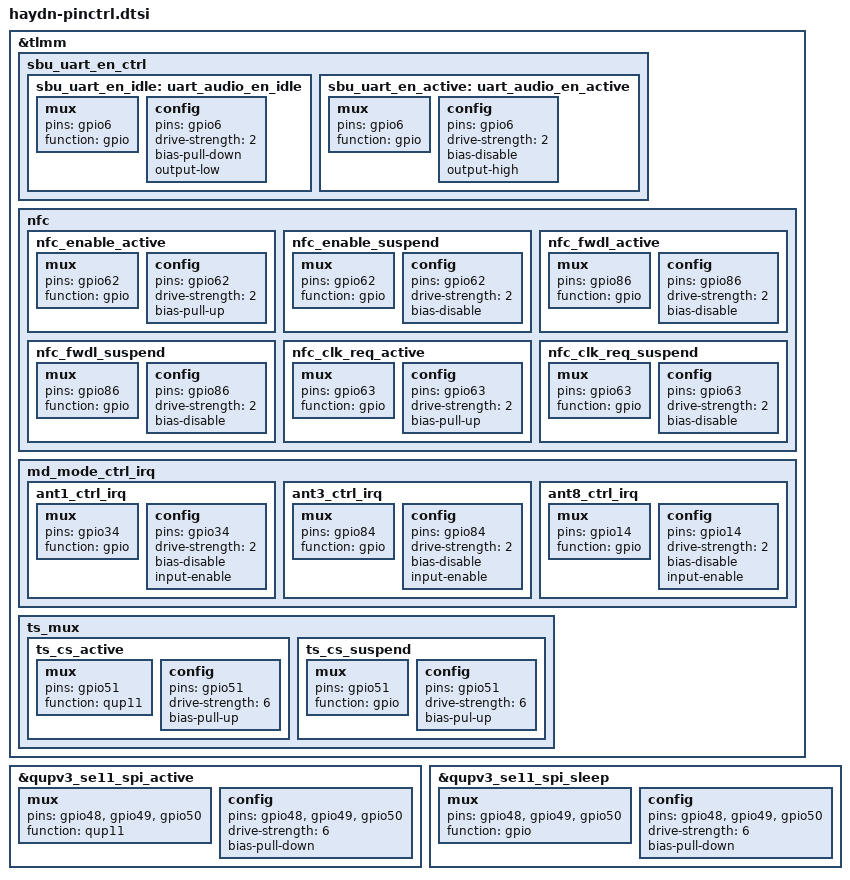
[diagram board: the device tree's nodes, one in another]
/*for haydn pinctrl */
&tlmm {
	sbu_uart_en_ctrl {
		sbu_uart_en_idle: uart_audio_en_idle {
			mux {
					pins = "gpio6";
					function = "gpio";
			};
			config {
					pins = "gpio6";
					drive-strength = <2>;
					bias-pull-down;
					output-low;
			};
		};

		sbu_uart_en_active: uart_audio_en_active {
			mux {
					pins = "gpio6";
					function = "gpio";
			};
			config {
						pins = "gpio6";
						drive-strength = <2>;
						bias-disable;
						output-high;
			};
		};
	};
	nfc {
			nfc_enable_active: nfc_enable_active {
				mux {
					pins = "gpio62";
					function = "gpio";
				};

				config {
					pins = "gpio62";
					drive-strength = <2>; /* 2 MA */
					bias-pull-up;
				};
			};

			nfc_enable_suspend: nfc_enable_suspend {
				mux {
					pins = "gpio62";
					function = "gpio";
				};

				config {
					pins = "gpio62";
					drive-strength = <2>; /* 2 MA */
					bias-disable;
				};
			};

			nfc_fwdl_active: nfc_fwdl_active {
				mux {
					/* 86: Firmware */
					pins = "gpio86";
					function = "gpio";
				};

				config {
					pins = "gpio86";
					drive-strength = <2>; /* 2 MA */
					bias-disable;
				};
			};

			nfc_fwdl_suspend: nfc_fwdl_suspend {
				mux {
					/*86: Firmware */
					pins = "gpio86";
					function = "gpio";
				};

				config {
					pins = "gpio86";
					drive-strength = <2>; /* 2 MA */
					bias-disable;
				};
			};

			nfc_clk_req_active: nfc_clk_req_active {
				/* active state */
				mux {
					/* GPIO 63: NFC CLOCK REQUEST */
					pins = "gpio63";
					function = "gpio";
				};

				config {
					pins = "gpio63";
					drive-strength = <2>; /* 2 MA */
					bias-pull-up;
				};
			};

			nfc_clk_req_suspend: nfc_clk_req_suspend {
				/* sleep state */
				mux {
					/* GPIO 63: NFC CLOCK REQUEST */
					pins = "gpio63";
					function = "gpio";
				};

				config {
					pins = "gpio63";
					drive-strength = <2>; /* 2 MA */
					bias-disable;
				};
			};
	};

	md_mode_ctrl_irq {
		ant1_ctrl_irq: ant1_ctrl_irq {
			mux {
				pins = "gpio34";
				function = "gpio";
			};

			config {
				pins = "gpio34";
				drive-strength = <2>;
				bias-disable;
				input-enable;
			};
		};

		ant3_ctrl_irq: ant3_ctrl_irq {
			mux {
				pins = "gpio84";
				function = "gpio";
			};

			config {
				pins = "gpio84";
				drive-strength = <2>;
				bias-disable;
				input-enable;
			};
		};

		ant8_ctrl_irq: ant8_ctrl_irq {
			mux {
				pins = "gpio14";
				function = "gpio";
			};

			config {
				pins = "gpio14";
				drive-strength = <2>;
				bias-disable;
				input-enable;
			};
		};
	};
	ts_mux {
		ts_cs_active: ts_cs_active {
			mux {
				pins = "gpio51";
				function = "qup11";
			};

			config {
				pins = "gpio51";
				drive-strength = <6>;
				bias-pull-up;
			};
		};

		ts_cs_suspend: ts_cs_suspend {
			mux {
				pins = "gpio51";
				function = "gpio";
			};

			config {
				pins = "gpio51";
				drive-strength = <6>;
				bias-pul-up;
			};
		};
	};
};

&qupv3_se11_spi_active {
	mux {
		pins = "gpio48", "gpio49", "gpio50";
		function = "qup11";
	};

	config {
		pins = "gpio48", "gpio49", "gpio50";
		drive-strength = <6>;
		bias-pull-down;
	};
};

&qupv3_se11_spi_sleep {
	mux {
		pins = "gpio48", "gpio49", "gpio50";
		function = "gpio";
	};

	config {
		pins = "gpio48", "gpio49", "gpio50";
		drive-strength = <6>;
		bias-pull-down;
	};
};

